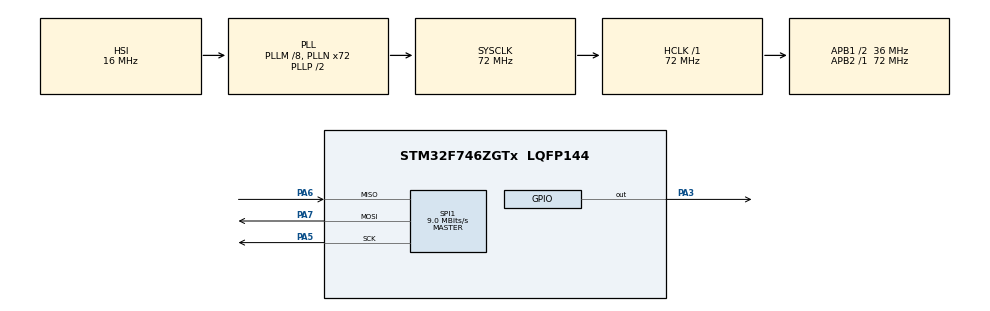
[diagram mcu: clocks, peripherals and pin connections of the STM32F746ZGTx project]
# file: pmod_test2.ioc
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Mcu.Family=STM32F7
Mcu.Name=STM32F746ZGTx
Mcu.Package=LQFP144
NVIC.PriorityGroup=NVIC_PRIORITYGROUP_4
PA3.Signal=GPIO_Output
PA5.Mode=Full_Duplex_Master
PA5.Signal=SPI1_SCK
PA6.Mode=Full_Duplex_Master
PA6.Signal=SPI1_MISO
PA7.Mode=Full_Duplex_Master
PA7.Signal=SPI1_MOSI
PH0/OSC_IN.Mode=HSE-External-Oscillator
PH0/OSC_IN.Signal=RCC_OSC_IN
PH1/OSC_OUT.Mode=HSE-External-Oscillator
PH1/OSC_OUT.Signal=RCC_OSC_OUT
ProjectManager.HeapSize=0x200
ProjectManager.StackSize=0x400
ProjectManager.TargetToolchain=STM32CubeIDE
RCC.48MHZClocksFreq_Value=24000000
RCC.AHBFreq_Value=72000000
RCC.APB1CLKDivider=RCC_HCLK_DIV2
RCC.APB1Freq_Value=36000000
RCC.APB1TimFreq_Value=72000000
RCC.APB2Freq_Value=72000000
RCC.APB2TimFreq_Value=72000000
RCC.CortexFreq_Value=72000000
RCC.HCLKFreq_Value=72000000
RCC.HSE_VALUE=8000000
RCC.HSI_VALUE=16000000
RCC.LSE_VALUE=32768
RCC.PLLM=8
RCC.PLLMUL=RCC_PLL_MUL9
RCC.PLLN=72
RCC.PLLQ=3
RCC.PRESCALERUSB=RCC_USBCLKSOURCE_PLL_DIV1_5
RCC.SYSCLKFreq_VALUE=72000000
RCC.SYSCLKSource=RCC_SYSCLKSOURCE_PLLCLK
RCC.SYSCLKSourceVirtual=RCC_SYSCLKSOURCE_PLLCLK
RCC.USBFreq_Value=48000000
RCC.VCOOutputFreq_Value=144000000
SPI1.BaudRatePrescaler=SPI_BAUDRATEPRESCALER_8
SPI1.CLKPhase=SPI_PHASE_2EDGE
SPI1.CalculateBaudRate=9.0 MBits/s
SPI1.DataSize=SPI_DATASIZE_16BIT
SPI1.Direction=SPI_DIRECTION_2LINES
SPI1.Mode=SPI_MODE_MASTER
SPI1.VirtualType=VM_MASTER
board=NUCLEO-F746ZG

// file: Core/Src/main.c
/* USER CODE BEGIN Header */
/**
  ******************************************************************************
  * @file           : main.c
  * @brief          : Main program body
  ******************************************************************************
  * @attention
  *
  * Copyright (c) 2023 STMicroelectronics.
  * All rights reserved.
  *
  * This software is licensed under terms that can be found in the LICENSE file
  * in the root directory of this software component.
  * If no LICENSE file comes with this software, it is provided AS-IS.
  *
  ******************************************************************************
  */
/* USER CODE END Header */
#include "main.h"

SPI_HandleTypeDef hspi1;

/* USER CODE BEGIN PV */
uint16_t val = 0;
uint16_t txData = 0;
/* USER CODE END PV */

void SystemClock_Config(void);
static void MX_GPIO_Init(void);
static void MX_SPI1_Init(void);

int main(void)
{

  /* MCU Configuration--------------------------------------------------------*/

  /* Reset of all peripherals, Initializes the Flash interface and the Systick. */
  HAL_Init();

  /* Configure the system clock */
  SystemClock_Config();

  /* Initialize all configured peripherals */
  MX_GPIO_Init();
  MX_SPI1_Init();
  /* USER CODE BEGIN 2 */
  HAL_GPIO_WritePin (GPIOA, GPIO_PIN_3, GPIO_PIN_SET);
  /* USER CODE END 2 */

  /* Infinite loop */
  /* USER CODE BEGIN WHILE */
  val =0;
  while (1)
  {
	for (val = 0; val<=4095 ; val++){
//	  uint8_t temp = (val*4095)/5;
		if(val == 4060) break;
	  HAL_GPIO_WritePin (GPIOA, GPIO_PIN_3, GPIO_PIN_RESET);
	  HAL_SPI_Transmit (&hspi1, (uint8_t *)&val, sizeof(val)/sizeof(uint16_t), 1);
	  HAL_GPIO_WritePin (GPIOA, GPIO_PIN_3, GPIO_PIN_SET);
//	  HAL_Delay(1);
	}

	for(val = 4095; val>=0; val--){
		if(val == 0) break;
	  HAL_GPIO_WritePin (GPIOA, GPIO_PIN_3, GPIO_PIN_RESET);
	  HAL_SPI_Transmit (&hspi1, (uint8_t *)&val, sizeof(val)/sizeof(uint16_t), 1);
	  HAL_GPIO_WritePin (GPIOA, GPIO_PIN_3, GPIO_PIN_SET);
//	  HAL_Delay(1);
	}
    /* USER CODE END WHILE */

    /* USER CODE BEGIN 3 */
//	  if(txData >= 4095) txData = 0;
//	  HAL_GPIO_WritePin (GPIOA, GPIO_PIN_3, GPIO_PIN_RESET);
//	  HAL_SPI_Transmit (&hspi1, (uint8_t *)&txData, sizeof(txData)/sizeof(uint16_t), HAL_MAX_DELAY);
//	  HAL_GPIO_WritePin (GPIOA, GPIO_PIN_3, GPIO_PIN_SET);
//	  txData+=2;
//	  HAL_Delay(1);

  }
  /* USER CODE END 3 */
}

void SystemClock_Config(void)
{
  RCC_OscInitTypeDef RCC_OscInitStruct = {0};
  RCC_ClkInitTypeDef RCC_ClkInitStruct = {0};

  /** Configure the main internal regulator output voltage
  */
  __HAL_RCC_PWR_CLK_ENABLE();
  __HAL_PWR_VOLTAGESCALING_CONFIG(PWR_REGULATOR_VOLTAGE_SCALE3);

  /** Initializes the RCC Oscillators according to the specified parameters
  * in the RCC_OscInitTypeDef structure.
  */
  RCC_OscInitStruct.OscillatorType = RCC_OSCILLATORTYPE_HSI;
  RCC_OscInitStruct.HSIState = RCC_HSI_ON;
  RCC_OscInitStruct.HSICalibrationValue = RCC_HSICALIBRATION_DEFAULT;
  RCC_OscInitStruct.PLL.PLLState = RCC_PLL_ON;
  RCC_OscInitStruct.PLL.PLLSource = RCC_PLLSOURCE_HSI;
  RCC_OscInitStruct.PLL.PLLM = 8;
  RCC_OscInitStruct.PLL.PLLN = 72;
  RCC_OscInitStruct.PLL.PLLP = RCC_PLLP_DIV2;
  RCC_OscInitStruct.PLL.PLLQ = 3;
  if (HAL_RCC_OscConfig(&RCC_OscInitStruct) != HAL_OK)
  {
    Error_Handler();
  }

  /** Initializes the CPU, AHB and APB buses clocks
  */
  RCC_ClkInitStruct.ClockType = RCC_CLOCKTYPE_HCLK|RCC_CLOCKTYPE_SYSCLK
                              |RCC_CLOCKTYPE_PCLK1|RCC_CLOCKTYPE_PCLK2;
  RCC_ClkInitStruct.SYSCLKSource = RCC_SYSCLKSOURCE_PLLCLK;
  RCC_ClkInitStruct.AHBCLKDivider = RCC_SYSCLK_DIV1;
  RCC_ClkInitStruct.APB1CLKDivider = RCC_HCLK_DIV2;
  RCC_ClkInitStruct.APB2CLKDivider = RCC_HCLK_DIV1;

  if (HAL_RCC_ClockConfig(&RCC_ClkInitStruct, FLASH_LATENCY_2) != HAL_OK)
  {
    Error_Handler();
  }
}

static void MX_SPI1_Init(void)
{

  /* SPI1 parameter configuration*/
  hspi1.Instance = SPI1;
  hspi1.Init.Mode = SPI_MODE_MASTER;
  hspi1.Init.Direction = SPI_DIRECTION_2LINES;
  hspi1.Init.DataSize = SPI_DATASIZE_16BIT;
  hspi1.Init.CLKPolarity = SPI_POLARITY_LOW;
  hspi1.Init.CLKPhase = SPI_PHASE_2EDGE;
  hspi1.Init.NSS = SPI_NSS_SOFT;
  hspi1.Init.BaudRatePrescaler = SPI_BAUDRATEPRESCALER_8;
  hspi1.Init.FirstBit = SPI_FIRSTBIT_MSB;
  hspi1.Init.TIMode = SPI_TIMODE_DISABLE;
  hspi1.Init.CRCCalculation = SPI_CRCCALCULATION_DISABLE;
  hspi1.Init.CRCPolynomial = 7;
  hspi1.Init.CRCLength = SPI_CRC_LENGTH_DATASIZE;
  hspi1.Init.NSSPMode = SPI_NSS_PULSE_DISABLE;
  if (HAL_SPI_Init(&hspi1) != HAL_OK)
  {
    Error_Handler();
  }

}

static void MX_GPIO_Init(void)
{
  GPIO_InitTypeDef GPIO_InitStruct = {0};

  /* GPIO Ports Clock Enable */
  __HAL_RCC_GPIOH_CLK_ENABLE();
  __HAL_RCC_GPIOA_CLK_ENABLE();

  /*Configure GPIO pin Output Level */
  HAL_GPIO_WritePin(GPIOA, GPIO_PIN_3, GPIO_PIN_RESET);

  /*Configure GPIO pin : PA3 */
  GPIO_InitStruct.Pin = GPIO_PIN_3;
  GPIO_InitStruct.Mode = GPIO_MODE_OUTPUT_PP;
  GPIO_InitStruct.Pull = GPIO_NOPULL;
  GPIO_InitStruct.Speed = GPIO_SPEED_FREQ_LOW;
  HAL_GPIO_Init(GPIOA, &GPIO_InitStruct);

}

void Error_Handler(void)
{
  __disable_irq();
  while (1)
  {
  }
}
